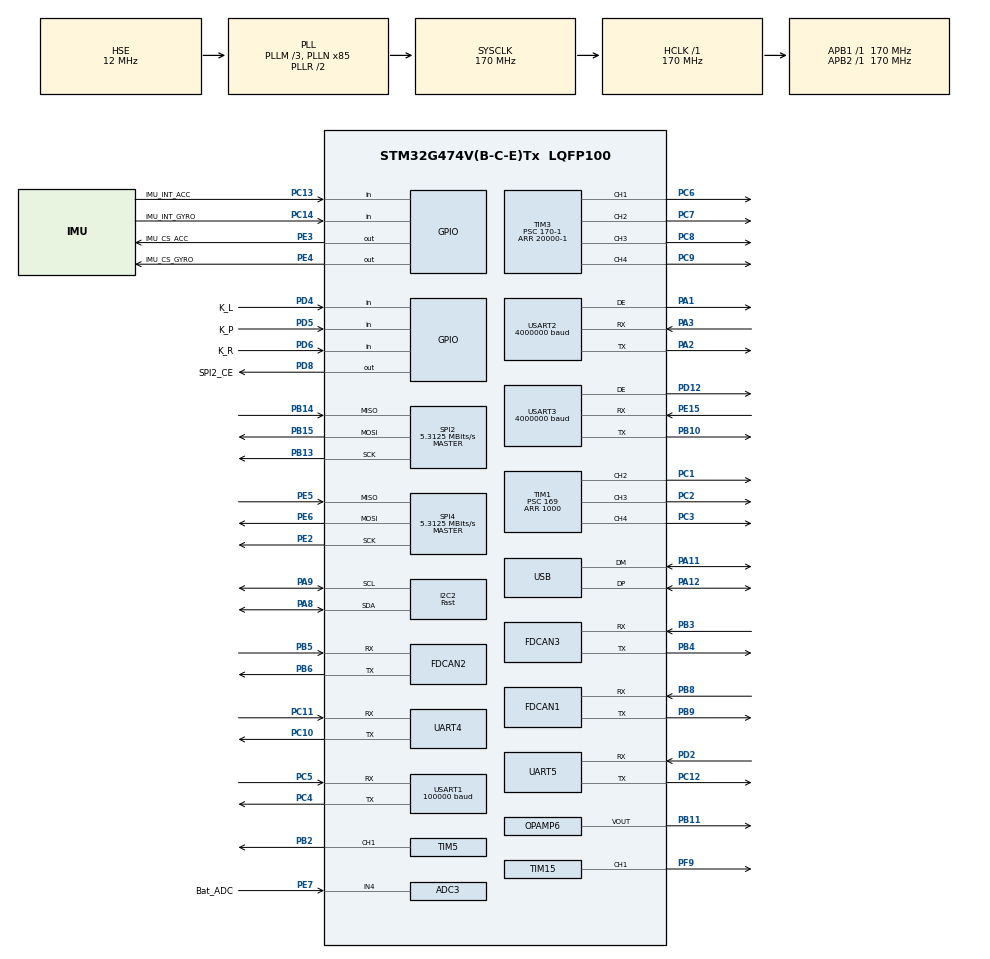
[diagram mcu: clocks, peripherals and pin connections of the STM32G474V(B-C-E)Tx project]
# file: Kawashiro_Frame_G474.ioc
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ADC3.Channel-0\#ChannelRegularConversion=ADC_CHANNEL_4
ADC3.NbrOfConversionFlag=1
ADC3.OffsetNumber-0\#ChannelRegularConversion=ADC_OFFSET_NONE
ADC3.Rank-0\#ChannelRegularConversion=1
ADC3.SamplingTime-0\#ChannelRegularConversion=ADC_SAMPLETIME_2CYCLES_5
ADC3.master=1
Dma.Request0=UART4_RX
Dma.Request1=UART5_RX
Dma.Request2=USART1_RX
Dma.Request3=USART2_RX
Dma.Request4=USART3_RX
Dma.Request5=UART4_TX
Dma.Request6=UART5_TX
Dma.Request7=USART1_TX
Dma.Request8=USART2_TX
Dma.Request9=USART3_TX
Dma.UART4_RX.0.Direction=DMA_PERIPH_TO_MEMORY
Dma.UART4_RX.0.EventEnable=DISABLE
Dma.UART4_RX.0.Instance=DMA1_Channel1
Dma.UART4_RX.0.MemDataAlignment=DMA_MDATAALIGN_BYTE
Dma.UART4_RX.0.MemInc=DMA_MINC_ENABLE
Dma.UART4_RX.0.Mode=DMA_NORMAL
Dma.UART4_RX.0.PeriphDataAlignment=DMA_PDATAALIGN_BYTE
Dma.UART4_RX.0.PeriphInc=DMA_PINC_DISABLE
Dma.UART4_RX.0.Polarity=HAL_DMAMUX_REQ_GEN_RISING
Dma.UART4_RX.0.Priority=DMA_PRIORITY_LOW
Dma.UART4_RX.0.RequestNumber=1
Dma.UART4_RX.0.SignalID=NONE
Dma.UART4_RX.0.SyncEnable=DISABLE
Dma.UART4_RX.0.SyncPolarity=HAL_DMAMUX_SYNC_NO_EVENT
Dma.UART4_RX.0.SyncRequestNumber=1
Dma.UART4_RX.0.SyncSignalID=NONE
Dma.UART4_TX.5.Direction=DMA_MEMORY_TO_PERIPH
Dma.UART4_TX.5.EventEnable=DISABLE
Dma.UART4_TX.5.Instance=DMA1_Channel6
Dma.UART4_TX.5.MemDataAlignment=DMA_MDATAALIGN_BYTE
Dma.UART4_TX.5.MemInc=DMA_MINC_ENABLE
Dma.UART4_TX.5.Mode=DMA_NORMAL
Dma.UART4_TX.5.PeriphDataAlignment=DMA_PDATAALIGN_BYTE
Dma.UART4_TX.5.PeriphInc=DMA_PINC_DISABLE
Dma.UART4_TX.5.Polarity=HAL_DMAMUX_REQ_GEN_RISING
Dma.UART4_TX.5.Priority=DMA_PRIORITY_LOW
Dma.UART4_TX.5.RequestNumber=1
Dma.UART4_TX.5.SignalID=NONE
Dma.UART4_TX.5.SyncEnable=DISABLE
Dma.UART4_TX.5.SyncPolarity=HAL_DMAMUX_SYNC_NO_EVENT
Dma.UART4_TX.5.SyncRequestNumber=1
Dma.UART4_TX.5.SyncSignalID=NONE
Dma.UART5_RX.1.Direction=DMA_PERIPH_TO_MEMORY
Dma.UART5_RX.1.EventEnable=ENABLE
Dma.UART5_RX.1.Instance=DMA1_Channel2
Dma.UART5_RX.1.MemDataAlignment=DMA_MDATAALIGN_BYTE
Dma.UART5_RX.1.MemInc=DMA_MINC_ENABLE
Dma.UART5_RX.1.Mode=DMA_NORMAL
Dma.UART5_RX.1.PeriphDataAlignment=DMA_PDATAALIGN_BYTE
Dma.UART5_RX.1.PeriphInc=DMA_PINC_DISABLE
Dma.UART5_RX.1.Polarity=HAL_DMAMUX_REQ_GEN_RISING
Dma.UART5_RX.1.Priority=DMA_PRIORITY_LOW
Dma.UART5_RX.1.RequestNumber=1
Dma.UART5_RX.1.SignalID=NONE
Dma.UART5_RX.1.SyncEnable=DISABLE
Dma.UART5_RX.1.SyncPolarity=HAL_DMAMUX_SYNC_NO_EVENT
Dma.UART5_RX.1.SyncRequestNumber=1
Dma.UART5_RX.1.SyncSignalID=NONE
Dma.UART5_TX.6.Direction=DMA_MEMORY_TO_PERIPH
Dma.UART5_TX.6.EventEnable=DISABLE
Dma.UART5_TX.6.Instance=DMA1_Channel7
Dma.UART5_TX.6.MemDataAlignment=DMA_MDATAALIGN_BYTE
Dma.UART5_TX.6.MemInc=DMA_MINC_ENABLE
Dma.UART5_TX.6.Mode=DMA_NORMAL
Dma.UART5_TX.6.PeriphDataAlignment=DMA_PDATAALIGN_BYTE
Dma.UART5_TX.6.PeriphInc=DMA_PINC_DISABLE
Dma.UART5_TX.6.Polarity=HAL_DMAMUX_REQ_GEN_RISING
Dma.UART5_TX.6.Priority=DMA_PRIORITY_LOW
Dma.UART5_TX.6.RequestNumber=1
Dma.UART5_TX.6.SignalID=NONE
Dma.UART5_TX.6.SyncEnable=DISABLE
Dma.UART5_TX.6.SyncPolarity=HAL_DMAMUX_SYNC_NO_EVENT
Dma.UART5_TX.6.SyncRequestNumber=1
Dma.UART5_TX.6.SyncSignalID=NONE
Dma.USART1_RX.2.Direction=DMA_PERIPH_TO_MEMORY
Dma.USART1_RX.2.EventEnable=DISABLE
Dma.USART1_RX.2.Instance=DMA1_Channel3
Dma.USART1_RX.2.MemDataAlignment=DMA_MDATAALIGN_BYTE
Dma.USART1_RX.2.MemInc=DMA_MINC_ENABLE
Dma.USART1_RX.2.Mode=DMA_NORMAL
Dma.USART1_RX.2.PeriphDataAlignment=DMA_PDATAALIGN_BYTE
Dma.USART1_RX.2.PeriphInc=DMA_PINC_DISABLE
Dma.USART1_RX.2.Polarity=HAL_DMAMUX_REQ_GEN_RISING
Dma.USART1_RX.2.Priority=DMA_PRIORITY_LOW
Dma.USART1_RX.2.RequestNumber=1
Dma.USART1_RX.2.SignalID=NONE
Dma.USART1_RX.2.SyncEnable=DISABLE
Dma.USART1_RX.2.SyncPolarity=HAL_DMAMUX_SYNC_NO_EVENT
Dma.USART1_RX.2.SyncRequestNumber=1
Dma.USART1_RX.2.SyncSignalID=NONE
Dma.USART1_TX.7.Direction=DMA_MEMORY_TO_PERIPH
Dma.USART1_TX.7.EventEnable=DISABLE
Dma.USART1_TX.7.Instance=DMA1_Channel8
Dma.USART1_TX.7.MemDataAlignment=DMA_MDATAALIGN_BYTE
Dma.USART1_TX.7.MemInc=DMA_MINC_ENABLE
Dma.USART1_TX.7.Mode=DMA_NORMAL
Dma.USART1_TX.7.PeriphDataAlignment=DMA_PDATAALIGN_BYTE
Dma.USART1_TX.7.PeriphInc=DMA_PINC_DISABLE
Dma.USART1_TX.7.Polarity=HAL_DMAMUX_REQ_GEN_RISING
Dma.USART1_TX.7.Priority=DMA_PRIORITY_LOW
Dma.USART1_TX.7.RequestNumber=1
Dma.USART1_TX.7.SignalID=NONE
Dma.USART1_TX.7.SyncEnable=DISABLE
Dma.USART1_TX.7.SyncPolarity=HAL_DMAMUX_SYNC_NO_EVENT
Dma.USART1_TX.7.SyncRequestNumber=1
Dma.USART1_TX.7.SyncSignalID=NONE
Dma.USART2_RX.3.Direction=DMA_PERIPH_TO_MEMORY
Dma.USART2_RX.3.EventEnable=DISABLE
Dma.USART2_RX.3.Instance=DMA1_Channel4
Dma.USART2_RX.3.MemDataAlignment=DMA_MDATAALIGN_BYTE
Dma.USART2_RX.3.MemInc=DMA_MINC_ENABLE
Dma.USART2_RX.3.Mode=DMA_NORMAL
Dma.USART2_RX.3.PeriphDataAlignment=DMA_PDATAALIGN_BYTE
Dma.USART2_RX.3.PeriphInc=DMA_PINC_DISABLE
Dma.USART2_RX.3.Polarity=HAL_DMAMUX_REQ_GEN_RISING
Dma.USART2_RX.3.Priority=DMA_PRIORITY_LOW
Dma.USART2_RX.3.RequestNumber=1
Dma.USART2_RX.3.SignalID=NONE
Dma.USART2_RX.3.SyncEnable=DISABLE
Dma.USART2_RX.3.SyncPolarity=HAL_DMAMUX_SYNC_NO_EVENT
Dma.USART2_RX.3.SyncRequestNumber=1
Dma.USART2_RX.3.SyncSignalID=NONE
Dma.USART2_TX.8.Direction=DMA_MEMORY_TO_PERIPH
Dma.USART2_TX.8.EventEnable=DISABLE
Dma.USART2_TX.8.Instance=DMA2_Channel1
Dma.USART2_TX.8.MemDataAlignment=DMA_MDATAALIGN_BYTE
Dma.USART2_TX.8.MemInc=DMA_MINC_ENABLE
Dma.USART2_TX.8.Mode=DMA_NORMAL
Dma.USART2_TX.8.PeriphDataAlignment=DMA_PDATAALIGN_BYTE
Dma.USART2_TX.8.PeriphInc=DMA_PINC_DISABLE
Dma.USART2_TX.8.Polarity=HAL_DMAMUX_REQ_GEN_RISING
Dma.USART2_TX.8.Priority=DMA_PRIORITY_LOW
Dma.USART2_TX.8.RequestNumber=1
Dma.USART2_TX.8.SignalID=NONE
Dma.USART2_TX.8.SyncEnable=DISABLE
Dma.USART2_TX.8.SyncPolarity=HAL_DMAMUX_SYNC_NO_EVENT
Dma.USART2_TX.8.SyncRequestNumber=1
Dma.USART2_TX.8.SyncSignalID=NONE
Dma.USART3_RX.4.Direction=DMA_PERIPH_TO_MEMORY
Dma.USART3_RX.4.EventEnable=DISABLE
Dma.USART3_RX.4.Instance=DMA1_Channel5
Dma.USART3_RX.4.MemDataAlignment=DMA_MDATAALIGN_BYTE
Dma.USART3_RX.4.MemInc=DMA_MINC_ENABLE
Dma.USART3_RX.4.Mode=DMA_NORMAL
Dma.USART3_RX.4.PeriphDataAlignment=DMA_PDATAALIGN_BYTE
Dma.USART3_RX.4.PeriphInc=DMA_PINC_DISABLE
Dma.USART3_RX.4.Polarity=HAL_DMAMUX_REQ_GEN_RISING
Dma.USART3_RX.4.Priority=DMA_PRIORITY_LOW
Dma.USART3_RX.4.RequestNumber=1
Dma.USART3_RX.4.SignalID=NONE
Dma.USART3_RX.4.SyncEnable=DISABLE
Dma.USART3_RX.4.SyncPolarity=HAL_DMAMUX_SYNC_NO_EVENT
Dma.USART3_RX.4.SyncRequestNumber=1
Dma.USART3_RX.4.SyncSignalID=NONE
Dma.USART3_TX.9.Direction=DMA_MEMORY_TO_PERIPH
Dma.USART3_TX.9.EventEnable=DISABLE
Dma.USART3_TX.9.Instance=DMA2_Channel2
Dma.USART3_TX.9.MemDataAlignment=DMA_MDATAALIGN_BYTE
Dma.USART3_TX.9.MemInc=DMA_MINC_ENABLE
Dma.USART3_TX.9.Mode=DMA_NORMAL
Dma.USART3_TX.9.PeriphDataAlignment=DMA_PDATAALIGN_BYTE
Dma.USART3_TX.9.PeriphInc=DMA_PINC_DISABLE
Dma.USART3_TX.9.Polarity=HAL_DMAMUX_REQ_GEN_RISING
Dma.USART3_TX.9.Priority=DMA_PRIORITY_LOW
Dma.USART3_TX.9.RequestNumber=1
Dma.USART3_TX.9.SignalID=NONE
Dma.USART3_TX.9.SyncEnable=DISABLE
Dma.USART3_TX.9.SyncPolarity=HAL_DMAMUX_SYNC_NO_EVENT
Dma.USART3_TX.9.SyncRequestNumber=1
Dma.USART3_TX.9.SyncSignalID=NONE
FDCAN1.AutoRetransmission=ENABLE
FDCAN1.CalculateBaudRateNominal=1000000
FDCAN1.CalculateTimeBitNominal=1000
FDCAN1.CalculateTimeQuantumNominal=100.0
FDCAN1.NominalPrescaler=17
FDCAN1.NominalTimeSeg1=4
FDCAN1.NominalTimeSeg2=5
FDCAN2.AutoRetransmission=ENABLE
FDCAN2.CalculateBaudRateNominal=1000000
FDCAN2.CalculateTimeBitNominal=1000
FDCAN2.CalculateTimeQuantumNominal=100.0
FDCAN2.NominalPrescaler=17
FDCAN2.NominalTimeSeg1=4
FDCAN2.NominalTimeSeg2=5
FDCAN3.AutoRetransmission=ENABLE
FDCAN3.CalculateBaudRateNominal=1000000
FDCAN3.CalculateTimeBitNominal=1000
FDCAN3.CalculateTimeQuantumNominal=100.0
FDCAN3.NominalPrescaler=17
FDCAN3.NominalTimeSeg1=4
FDCAN3.NominalTimeSeg2=5
FREERTOS.Tasks01=defaultTask,0,128,StartDefaultTask,Default,NULL,Dynamic,NULL,NULL;Robo,-3,512,Robo_Task,Default,NULL,Dynamic,NULL,NULL;INS,-3,1024,INS_Task,Default,NULL,Dynamic,NULL,NULL;Gimbal,-3,1024,Gimbal_Task,Default,NULL,Dynamic,NULL,NULL;Chassis,-3,1024,Chassis_Task,Default,NULL,Dynamic,NULL,NULL;Communicate,-3,512,Communicate_Task,Default,NULL,Dynamic,NULL,NULL;Key_LED,-3,256,Key_LED_Task,Default,NULL,Dynamic,NULL,NULL;Buzzer,-3,256,Buzzer_Task,Default,NULL,Dynamic,NULL,NULL;UI,-3,256,UI_Task,Default,NULL,Dynamic,NULL,NULL;Shoot,-3,1024,Shoot_Task,Default,NULL,Dynamic,NULL,NULL;Aim,-3,512,Aim_Task,Default,NULL,Dynamic,NULL,NULL;ErrorHandle,-3,256,ErrorHandle_Task,Default,NULL,Dynamic,NULL,NULL
FREERTOS.configTOTAL_HEAP_SIZE=32768
I2C2.I2C_Speed_Mode=I2C_Fast
I2C2.Timing=0x40621236
Mcu.Family=STM32G4
Mcu.Name=STM32G474V(B-C-E)Tx
Mcu.Package=LQFP100
NVIC.DMA1_Channel1_IRQn=true\:4\:0\:true\:false\:true\:false\:false\:true\:true
NVIC.DMA1_Channel2_IRQn=true\:4\:0\:true\:false\:true\:false\:false\:true\:true
NVIC.DMA1_Channel3_IRQn=true\:4\:0\:true\:false\:true\:false\:false\:true\:true
NVIC.DMA1_Channel4_IRQn=true\:4\:0\:true\:false\:true\:false\:false\:true\:true
NVIC.DMA1_Channel5_IRQn=true\:4\:0\:true\:false\:true\:false\:false\:true\:true
NVIC.DMAMUX_OVR_IRQn=true\:5\:0\:false\:false\:true\:false\:false\:true\:true
NVIC.FDCAN1_IT0_IRQn=true\:5\:0\:false\:false\:true\:true\:true\:true\:true
NVIC.FDCAN1_IT1_IRQn=true\:5\:0\:false\:false\:true\:true\:true\:true\:true
NVIC.FDCAN2_IT0_IRQn=true\:5\:0\:false\:false\:true\:true\:true\:true\:true
NVIC.FDCAN2_IT1_IRQn=true\:5\:0\:false\:false\:true\:true\:true\:true\:true
NVIC.FDCAN3_IT0_IRQn=true\:5\:0\:false\:false\:true\:true\:true\:true\:true
NVIC.FDCAN3_IT1_IRQn=true\:5\:0\:false\:false\:true\:true\:true\:true\:true
NVIC.PriorityGroup=NVIC_PRIORITYGROUP_4
NVIC.TIM20_UP_IRQn=true\:15\:0\:false\:false\:true\:false\:false\:true\:true
NVIC.TimeBase=TIM20_UP_IRQn
NVIC.TimeBaseIP=TIM20
NVIC.UART4_IRQn=true\:4\:0\:true\:false\:true\:false\:true\:true\:true
NVIC.UART5_IRQn=true\:4\:0\:true\:false\:true\:false\:true\:true\:true
NVIC.USART1_IRQn=true\:4\:0\:true\:false\:true\:false\:true\:true\:true
NVIC.USART2_IRQn=true\:4\:0\:true\:false\:true\:false\:true\:true\:true
NVIC.USART3_IRQn=true\:4\:0\:true\:false\:true\:false\:true\:true\:true
NVIC.USB_LP_IRQn=true\:5\:0\:false\:false\:true\:true\:false\:true\:true
PA1.GPIO_Mode=GPIO_MODE_AF_PP
PA1.GPIO_PuPd=GPIO_PULLDOWN
PA1.GPIO_Speed=GPIO_SPEED_FREQ_HIGH
PA1.Mode=Hardware Flow Control (RS485)
PA1.Signal=USART2_DE
PA11.Mode=Device
PA11.Signal=USB_DM
PA12.Mode=Device
PA12.Signal=USB_DP
PA13.Mode=Serial_Wire
PA13.Signal=SYS_JTMS-SWDIO
PA14.Mode=Serial_Wire
PA14.Signal=SYS_JTCK-SWCLK
PA2.GPIO_Mode=GPIO_MODE_AF_PP
PA2.GPIO_PuPd=GPIO_PULLUP
PA2.GPIO_Speed=GPIO_SPEED_FREQ_HIGH
PA2.Mode=Asynchronous
PA2.Signal=USART2_TX
PA3.GPIO_Mode=GPIO_MODE_AF_PP
PA3.GPIO_PuPd=GPIO_PULLUP
PA3.GPIO_Speed=GPIO_SPEED_FREQ_HIGH
PA3.Mode=Asynchronous
PA3.Signal=USART2_RX
PA8.GPIO_Mode=GPIO_MODE_AF_OD
PA8.GPIO_Pu=GPIO_PULLUP
PA8.GPIO_Speed=GPIO_SPEED_FREQ_HIGH
PA8.Mode=I2C
PA8.Signal=I2C2_SDA
PA9.GPIO_Mode=GPIO_MODE_AF_OD
PA9.GPIO_Pu=GPIO_PULLUP
PA9.GPIO_Speed=GPIO_SPEED_FREQ_HIGH
PA9.Mode=I2C
PA9.Signal=I2C2_SCL
PB10.GPIO_Mode=GPIO_MODE_AF_PP
PB10.GPIO_PuPd=GPIO_PULLUP
PB10.GPIO_Speed=GPIO_SPEED_FREQ_HIGH
PB10.Mode=Asynchronous
PB10.Signal=USART3_TX
PB11.Mode=Follower-DAC_OUT2-INP
PB11.Signal=OPAMP6_VOUT
PB13.Mode=Full_Duplex_Master
PB13.Signal=SPI2_SCK
PB14.Mode=Full_Duplex_Master
PB14.Signal=SPI2_MISO
PB15.Mode=Full_Duplex_Master
PB15.Signal=SPI2_MOSI
PB2.Signal=S_TIM5_CH1
PB3.Mode=FDCAN_Activate
PB3.Signal=FDCAN3_RX
PB4.Mode=FDCAN_Activate
PB4.Signal=FDCAN3_TX
PB5.Mode=FDCAN_Activate
PB5.Signal=FDCAN2_RX
PB6.Mode=FDCAN_Activate
PB6.Signal=FDCAN2_TX
PB8-BOOT0.Mode=FDCAN_Activate
PB8-BOOT0.Signal=FDCAN1_RX
PB9.Mode=FDCAN_Activate
PB9.Signal=FDCAN1_TX
PC1.Signal=S_TIM1_CH2
PC10.GPIO_ModeDefaultPP=GPIO_MODE_AF_PP
PC10.GPIO_PuPd=GPIO_PULLUP
PC10.GPIO_Speed=GPIO_SPEED_FREQ_VERY_HIGH
PC10.Mode=Asynchronous
PC10.Signal=UART4_TX
PC11.GPIO_ModeDefaultPP=GPIO_MODE_AF_PP
PC11.GPIO_PuPd=GPIO_PULLUP
PC11.GPIO_Speed=GPIO_SPEED_FREQ_VERY_HIGH
PC11.Mode=Asynchronous
PC11.Signal=UART4_RX
PC12.GPIO_ModeDefaultPP=GPIO_MODE_AF_PP
PC12.GPIO_PuPd=GPIO_PULLUP
PC12.GPIO_Speed=GPIO_SPEED_FREQ_VERY_HIGH
PC12.Mode=Asynchronous
PC12.Signal=UART5_TX
PC13.GPIO_Label=IMU_INT_ACC
PC13.Signal=GPIO_Input
PC14-OSC32_IN.GPIO_Label=IMU_INT_GYRO
PC14-OSC32_IN.Signal=GPIO_Input
PC2.Signal=S_TIM1_CH3
PC3.Signal=S_TIM1_CH4
PC4.GPIO_Mode=GPIO_MODE_AF_PP
PC4.GPIO_PuPd=GPIO_PULLUP
PC4.GPIO_Speed=GPIO_SPEED_FREQ_HIGH
PC4.Mode=Asynchronous
PC4.Signal=USART1_TX
PC5.GPIO_Mode=GPIO_MODE_AF_PP
PC5.GPIO_PuPd=GPIO_PULLUP
PC5.GPIO_Speed=GPIO_SPEED_FREQ_HIGH
PC5.Mode=Asynchronous
PC5.Signal=USART1_RX
PC6.Signal=S_TIM3_CH1
PC7.Signal=S_TIM3_CH2
PC8.Signal=S_TIM3_CH3
PC9.Signal=S_TIM3_CH4
PD12.GPIO_Mode=GPIO_MODE_AF_PP
PD12.GPIO_PuPd=GPIO_PULLDOWN
PD12.GPIO_Speed=GPIO_SPEED_FREQ_HIGH
PD12.Mode=Hardware Flow Control (RS485)
PD12.Signal=USART3_DE
PD2.GPIO_ModeDefaultPP=GPIO_MODE_AF_PP
PD2.GPIO_PuPd=GPIO_PULLUP
PD2.GPIO_Speed=GPIO_SPEED_FREQ_VERY_HIGH
PD2.Mode=Asynchronous
PD2.Signal=UART5_RX
PD4.GPIO_Label=K_L
PD4.GPIO_Mode=GPIO_MODE_INPUT
PD4.GPIO_PuPd=GPIO_PULLUP
PD4.Signal=GPIO_Input
PD5.GPIO_Label=K_P
PD5.GPIO_Mode=GPIO_MODE_INPUT
PD5.GPIO_PuPd=GPIO_PULLUP
PD5.Signal=GPIO_Input
PD6.GPIO_Label=K_R
PD6.GPIO_Mode=GPIO_MODE_INPUT
PD6.GPIO_PuPd=GPIO_PULLUP
PD6.Signal=GPIO_Input
PD8.GPIO_Label=SPI2_CE
PD8.GPIO_ModeDefaultOutputPP=GPIO_MODE_OUTPUT_PP
PD8.GPIO_PuPd=GPIO_PULLUP
PD8.GPIO_Speed=GPIO_SPEED_FREQ_HIGH
PD8.PinState=GPIO_PIN_SET
PD8.Signal=GPIO_Output
PE15.GPIO_Mode=GPIO_MODE_AF_PP
PE15.GPIO_PuPd=GPIO_PULLUP
PE15.GPIO_Speed=GPIO_SPEED_FREQ_HIGH
PE15.Mode=Asynchronous
PE15.Signal=USART3_RX
PE2.GPIO_Speed=GPIO_SPEED_FREQ_VERY_HIGH
PE2.Mode=Full_Duplex_Master
PE2.Signal=SPI4_SCK
PE3.GPIO_Label=IMU_CS_ACC
PE3.GPIO_ModeDefaultOutputPP=GPIO_MODE_OUTPUT_PP
PE3.GPIO_PuPd=GPIO_PULLUP
PE3.GPIO_Speed=GPIO_SPEED_FREQ_HIGH
PE3.PinState=GPIO_PIN_SET
PE3.Signal=GPIO_Output
PE4.GPIO_Label=IMU_CS_GYRO
PE4.GPIO_ModeDefaultOutputPP=GPIO_MODE_OUTPUT_PP
PE4.GPIO_PuPd=GPIO_PULLUP
PE4.GPIO_Speed=GPIO_SPEED_FREQ_HIGH
PE4.PinState=GPIO_PIN_SET
PE4.Signal=GPIO_Output
PE5.GPIO_Speed=GPIO_SPEED_FREQ_VERY_HIGH
PE5.Mode=Full_Duplex_Master
PE5.Signal=SPI4_MISO
PE6.GPIO_Speed=GPIO_SPEED_FREQ_VERY_HIGH
PE6.Mode=Full_Duplex_Master
PE6.Signal=SPI4_MOSI
PE7.GPIO_Label=Bat_ADC
PE7.Mode=IN4-Single-Ended
PE7.Signal=ADC3_IN4
PF0-OSC_IN.Mode=HSE-External-Oscillator
PF0-OSC_IN.Signal=RCC_OSC_IN
PF1-OSC_OUT.Mode=HSE-External-Oscillator
PF1-OSC_OUT.Signal=RCC_OSC_OUT
PF9.Signal=S_TIM15_CH1
ProjectManager.HeapSize=0x2000
ProjectManager.StackSize=0x4000
ProjectManager.TargetToolchain=MDK-ARM V5.32
RCC.ADC12Freq_Value=170000000
RCC.ADC345Freq_Value=170000000
RCC.AHBFreq_Value=170000000
RCC.APB1Freq_Value=170000000
RCC.APB1TimFreq_Value=170000000
RCC.APB2Freq_Value=170000000
RCC.APB2TimFreq_Value=170000000
RCC.CK48CLockSelection=RCC_USBCLKSOURCE_HSI48
RCC.CortexFreq_Value=170000000
RCC.EXTERNAL_CLOCK_VALUE=12288000
RCC.HCLKFreq_Value=170000000
RCC.HSE_VALUE=12000000
RCC.HSI48_VALUE=48000000
RCC.HSI_VALUE=16000000
RCC.LSE_VALUE=32768
RCC.PLLM=RCC_PLLM_DIV3
RCC.PLLN=85
RCC.PLLQ=RCC_PLLQ_DIV8
RCC.PLLSourceVirtual=RCC_PLLSOURCE_HSE
RCC.SYSCLKFreq_VALUE=170000000
RCC.SYSCLKSource=RCC_SYSCLKSOURCE_PLLCLK
RCC.USBFreq_Value=48000000
RCC.VCOOutputFreq_Value=340000000
SH.S_TIM15_CH1.0=TIM15_CH1,PWM Generation1 CH1
SH.S_TIM1_CH2.0=TIM1_CH2,PWM Generation2 CH2
SH.S_TIM1_CH3.0=TIM1_CH3,PWM Generation3 CH3
SH.S_TIM1_CH4.0=TIM1_CH4,PWM Generation4 CH4
SH.S_TIM3_CH1.0=TIM3_CH1,PWM Generation1 CH1
SH.S_TIM3_CH2.0=TIM3_CH2,PWM Generation2 CH2
SH.S_TIM3_CH3.0=TIM3_CH3,PWM Generation3 CH3
SH.S_TIM3_CH4.0=TIM3_CH4,PWM Generation4 CH4
SH.S_TIM5_CH1.0=TIM5_CH1,PWM Generation1 CH1
SPI2.BaudRatePrescaler=SPI_BAUDRATEPRESCALER_32
SPI2.CalculateBaudRate=5.3125 MBits/s
SPI2.DataSize=SPI_DATASIZE_8BIT
SPI2.Direction=SPI_DIRECTION_2LINES
SPI2.Mode=SPI_MODE_MASTER
SPI2.VirtualType=VM_MASTER
SPI4.BaudRatePrescaler=SPI_BAUDRATEPRESCALER_32
SPI4.CLKPhase=SPI_PHASE_2EDGE
SPI4.CLKPolarity=SPI_POLARITY_HIGH
SPI4.CalculateBaudRate=5.3125 MBits/s
SPI4.DataSize=SPI_DATASIZE_8BIT
SPI4.Direction=SPI_DIRECTION_2LINES
SPI4.Mode=SPI_MODE_MASTER
SPI4.VirtualType=VM_MASTER
TIM1.Channel-PWM\ Generation2\ CH2=TIM_CHANNEL_2
TIM1.Channel-PWM\ Generation3\ CH3=TIM_CHANNEL_3
TIM1.Channel-PWM\ Generation4\ CH4=TIM_CHANNEL_4
TIM1.OCPolarity_2=TIM_OCPOLARITY_LOW
TIM1.OCPolarity_3=TIM_OCPOLARITY_LOW
TIM1.OCPolarity_4=TIM_OCPOLARITY_LOW
TIM1.PeriodNoDither=1000
TIM1.Prescaler=169
TIM15.Channel-PWM\ Generation1\ CH1=TIM_CHANNEL_1
TIM15.PeriodNoDither=20000-1
TIM15.Prescaler=170-1
TIM3.Channel-PWM\ Generation1\ CH1=TIM_CHANNEL_1
TIM3.Channel-PWM\ Generation2\ CH2=TIM_CHANNEL_2
TIM3.Channel-PWM\ Generation3\ CH3=TIM_CHANNEL_3
TIM3.Channel-PWM\ Generation4\ CH4=TIM_CHANNEL_4
TIM3.PeriodNoDither=20000-1
TIM3.Prescaler=170-1
TIM5.AutoReloadPreload=TIM_AUTORELOAD_PRELOAD_ENABLE
TIM5.Channel-PWM\ Generation1\ CH1=TIM_CHANNEL_1
TIM5.OC1Preload_PWM=DISABLE
TIM5.OCFastMode_PWM-PWM\ Generation1\ CH1=TIM_OCFAST_ENABLE
TIM5.PeriodNoDither=1000-1
TIM5.Prescaler=170-1
USART1.BaudRate=100000
USART1.Parity=PARITY_EVEN
USART1.VirtualMode-Asynchronous=VM_ASYNC
USART1.WordLength=WORDLENGTH_9B
USART2.BaudRate=4000000
USART2.VirtualMode-Asynchronous=VM_ASYNC
USART2.VirtualMode-Hardware\ Flow\ Control\ (RS485)=VM_ASYNC
USART3.BaudRate=4000000
USART3.VirtualMode-Asynchronous=VM_ASYNC
USART3.VirtualMode-Hardware\ Flow\ Control\ (RS485)=VM_ASYNC
USB_DEVICE.CLASS_NAME_FS=CDC
USB_DEVICE.VirtualMode=Cdc
USB_DEVICE.VirtualModeFS=Cdc_FS
VP_CRC_VS_CRC.Mode=CRC_Activate
VP_DAC3_VS_DACI1.Mode=DAC_OUT1_Int
VP_FREERTOS_VS_CMSIS_V1.Mode=CMSIS_V1
VP_SYS_VS_DBSignals.Mode=DisableDeadBatterySignals
VP_SYS_VS_tim20.Mode=TIM20
VP_TIM15_VS_ClockSourceINT.Mode=Internal
VP_TIM1_VS_ClockSourceINT.Mode=Internal
VP_TIM3_VS_ClockSourceINT.Mode=Internal
VP_TIM5_VS_ClockSourceINT.Mode=Internal
VP_USB_DEVICE_VS_USB_DEVICE_CDC_FS.Mode=CDC_FS
board=custom

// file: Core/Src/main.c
/* USER CODE BEGIN Header */
/**
  ******************************************************************************
  * @file           : main.c
  * @brief          : Main program body
  ******************************************************************************
  * @attention
  *
  * Copyright (c) 2024 STMicroelectronics.
  * All rights reserved.
  *
  * This software is licensed under terms that can be found in the LICENSE file
  * in the root directory of this software component.
  * If no LICENSE file comes with this software, it is provided AS-IS.
  *
  ******************************************************************************
  */
/* USER CODE END Header */
#include "main.h"
#include "cmsis_os.h"
#include "adc.h"
#include "crc.h"
#include "dac.h"
#include "dma.h"
#include "fdcan.h"
#include "i2c.h"
#include "opamp.h"
#include "spi.h"
#include "tim.h"
#include "usart.h"
#include "usb_device.h"
#include "gpio.h"

/* USER CODE BEGIN Includes */
#include "bmi088driver.h"
#include "CAN_Driver.h"
#include "USART_Driver.h"
#include "Buzzer.h"
#include "USB_Driver.h"
/* USER CODE END Includes */

void SystemClock_Config(void);
void MX_FREERTOS_Init(void);

int main(void)
{

  /* MCU Configuration--------------------------------------------------------*/

  /* Reset of all peripherals, Initializes the Flash interface and the Systick. */
  HAL_Init();

  /* Configure the system clock */
  SystemClock_Config();

  /* Initialize all configured peripherals */
  MX_GPIO_Init();
  MX_DMA_Init();
  MX_FDCAN1_Init();
  MX_FDCAN2_Init();
  MX_FDCAN3_Init();
  MX_UART4_Init();
  MX_UART5_Init();
  MX_USART1_UART_Init();
  MX_USART2_UART_Init();
  MX_USART3_UART_Init();
  MX_ADC3_Init();
  MX_DAC3_Init();
  MX_I2C2_Init();
  MX_OPAMP6_Init();
  MX_SPI2_Init();
  MX_SPI4_Init();
  MX_TIM1_Init();
  MX_TIM3_Init();
  MX_TIM5_Init();
  MX_TIM15_Init();
  MX_CRC_Init();
  /* USER CODE BEGIN 2 */
    /*===| 蜂鸣器 |===*/
        Buzzer_Init();
//        Buzzer_Set_Tone(L3);

        /*===| 初始化DWT |===*/
        DWT_Init(170);

        /*===| 等待陀螺仪校准 |===*/
        while (BMI088_init(IMU_SPI, 1) != BMI088_NO_ERROR);

        /*===| 通信初始化 |===*/
        CAN_Init();                                             //CAN初始化
        USART_Init();                                           //串口初始化

        /*===| 系统初始化完成提示音 |===*/
        Buzzer_Set_SoundEffect(Buzzer_SoundEffect_SystemStart);
  /* USER CODE END 2 */

  /* Call init function for freertos objects (in cmsis_os2.c) */
  MX_FREERTOS_Init();

  /* Start scheduler */
  osKernelStart();

  /* We should never get here as control is now taken by the scheduler */

  /* Infinite loop */
  while (1)
  {

  }
}

void SystemClock_Config(void)
{
  RCC_OscInitTypeDef RCC_OscInitStruct = {0};
  RCC_ClkInitTypeDef RCC_ClkInitStruct = {0};

  /** Configure the main internal regulator output voltage
  */
  HAL_PWREx_ControlVoltageScaling(PWR_REGULATOR_VOLTAGE_SCALE1_BOOST);

  /** Initializes the RCC Oscillators according to the specified parameters
  * in the RCC_OscInitTypeDef structure.
  */
  RCC_OscInitStruct.OscillatorType = RCC_OSCILLATORTYPE_HSI48|RCC_OSCILLATORTYPE_HSE;
  RCC_OscInitStruct.HSEState = RCC_HSE_ON;
  RCC_OscInitStruct.HSI48State = RCC_HSI48_ON;
  RCC_OscInitStruct.PLL.PLLState = RCC_PLL_ON;
  RCC_OscInitStruct.PLL.PLLSource = RCC_PLLSOURCE_HSE;
  RCC_OscInitStruct.PLL.PLLM = RCC_PLLM_DIV3;
  RCC_OscInitStruct.PLL.PLLN = 85;
  RCC_OscInitStruct.PLL.PLLP = RCC_PLLP_DIV2;
  RCC_OscInitStruct.PLL.PLLQ = RCC_PLLQ_DIV8;
  RCC_OscInitStruct.PLL.PLLR = RCC_PLLR_DIV2;
  if (HAL_RCC_OscConfig(&RCC_OscInitStruct) != HAL_OK)
  {
    Error_Handler();
  }

  /** Initializes the CPU, AHB and APB buses clocks
  */
  RCC_ClkInitStruct.ClockType = RCC_CLOCKTYPE_HCLK|RCC_CLOCKTYPE_SYSCLK
                              |RCC_CLOCKTYPE_PCLK1|RCC_CLOCKTYPE_PCLK2;
  RCC_ClkInitStruct.SYSCLKSource = RCC_SYSCLKSOURCE_PLLCLK;
  RCC_ClkInitStruct.AHBCLKDivider = RCC_SYSCLK_DIV1;
  RCC_ClkInitStruct.APB1CLKDivider = RCC_HCLK_DIV1;
  RCC_ClkInitStruct.APB2CLKDivider = RCC_HCLK_DIV1;

  if (HAL_RCC_ClockConfig(&RCC_ClkInitStruct, FLASH_LATENCY_4) != HAL_OK)
  {
    Error_Handler();
  }
}

void HAL_TIM_PeriodElapsedCallback(TIM_HandleTypeDef *htim)
{
  if (htim->Instance == TIM20) {
    HAL_IncTick();
  }
}

void Error_Handler(void)
{
  __disable_irq();
  while (1)
  {
  }
}
